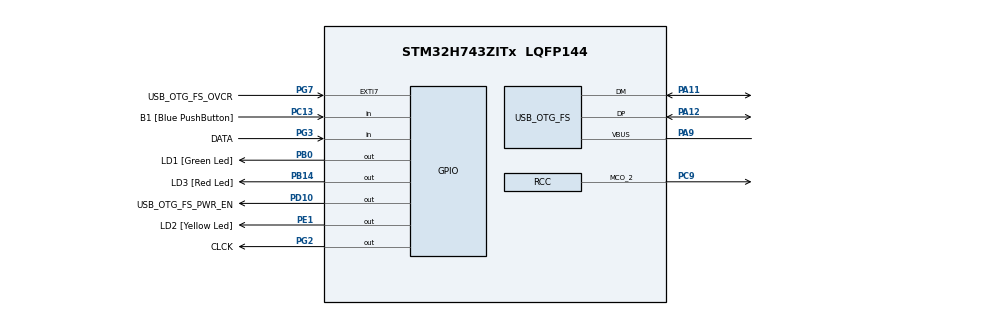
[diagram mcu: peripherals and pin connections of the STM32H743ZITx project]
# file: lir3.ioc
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Mcu.Family=STM32H7
Mcu.Name=STM32H743ZITx
Mcu.Package=LQFP144
NVIC.OTG_FS_IRQn=true\:0\:0\:false\:false\:true\:false\:true
NVIC.PriorityGroup=NVIC_PRIORITYGROUP_4
NVIC.TIM1_UP_IRQn=true\:0\:0\:false\:false\:true\:true\:true
NVIC.TIM2_IRQn=true\:0\:0\:false\:false\:true\:true\:true
PA11.Mode=Device_Only
PA11.Signal=USB_OTG_FS_DM
PA12.Mode=Device_Only
PA12.Signal=USB_OTG_FS_DP
PA13\ (JTMS/SWDIO).Mode=Serial_Wire
PA13\ (JTMS/SWDIO).Signal=DEBUG_JTMS-SWDIO
PA14\ (JTCK/SWCLK).Mode=Serial_Wire
PA14\ (JTCK/SWCLK).Signal=DEBUG_JTCK-SWCLK
PA8.Signal=USB_OTG_FS_SOF
PA9.Mode=Activate_VBUS
PA9.Signal=USB_OTG_FS_VBUS
PB0.GPIO_Label=LD1 [Green Led]
PB0.Signal=GPIO_Output
PB14.GPIO_Label=LD3 [Red Led]
PB14.Signal=GPIO_Output
PC1.Signal=SAI1_SD_A
PC13.GPIO_Label=B1 [Blue PushButton]
PC13.Signal=GPIO_Input
PC14-OSC32_IN\ (OSC32_IN).Signal=RCC_OSC32_IN
PC15-OSC32_OUT\ (OSC32_OUT).Signal=RCC_OSC32_OUT
PC9.Mode=Clock-out-2
PC9.Signal=RCC_MCO_2
PD10.GPIO_Label=USB_OTG_FS_PWR_EN
PD10.Signal=GPIO_Output
PD8.GPIO_Label=STLINK_RX
PD8.Signal=USART3_TX
PD9.GPIO_Label=STLINK_TX
PD9.Signal=USART3_RX
PE1.GPIO_Label=LD2 [Yellow Led]
PE1.Signal=GPIO_Output
PG2.GPIO_Label=CLCK
PG2.GPIO_PuPd=GPIO_PULLUP
PG2.GPIO_Speed=GPIO_SPEED_FREQ_LOW
PG2.PinState=GPIO_PIN_SET
PG2.Signal=GPIO_Output
PG3.GPIO_Label=DATA
PG3.GPIO_PuPd=GPIO_PULLUP
PG3.Signal=GPIO_Input
PG7.GPIO_Label=USB_OTG_FS_OVCR
PG7.Signal=GPXTI7
PH0-OSC_IN\ (PH0).Mode=HSE-External-Oscillator
PH0-OSC_IN\ (PH0).Signal=RCC_OSC_IN
PH1-OSC_OUT\ (PH1).Mode=HSE-External-Oscillator
PH1-OSC_OUT\ (PH1).Signal=RCC_OSC_OUT
ProjectManager.HeapSize=0x200
ProjectManager.StackSize=0x400
ProjectManager.TargetToolchain=STM32CubeIDE
RCC.ADCFreq_Value=129000000
RCC.APB1Freq_Value=120000000
RCC.APB2Freq_Value=120000000
RCC.APB3Freq_Value=120000000
RCC.APB4Freq_Value=120000000
RCC.CortexFreq_Value=480000000
RCC.D1PPRE=RCC_APB3_DIV2
RCC.D2PPRE1=RCC_APB1_DIV2
RCC.D2PPRE2=RCC_APB2_DIV2
RCC.D3PPRE=RCC_APB4_DIV2
RCC.DIVM1=12
RCC.DIVN1=180
RCC.HCLKFreq_Value=240000000
RCC.HPRE=RCC_HCLK_DIV2
RCC.HSE_VALUE=25000000
RCC.SYSCLKFreq_VALUE=480000000
RCC.SYSCLKSource=RCC_SYSCLKSOURCE_PLLCLK
RCC.USBCLockSelection=RCC_USBCLKSOURCE_HSI48
RCC.USBFreq_Value=48000000
TIM1.Period=24
TIM1.Prescaler=23
TIM2.Channel-Output\ Compare1\ No\ Output=TIM_CHANNEL_1
TIM2.Period=149
TIM2.Prescaler=239
USB_DEVICE.CLASS_NAME_FS=CDC
USB_DEVICE.VirtualMode-CDC_FS=Cdc
USB_DEVICE.VirtualModeFS=Cdc_FS
USB_OTG_FS.VirtualMode=Device_Only
VP_TIM1_VS_ClockSourceINT.Mode=Internal
VP_TIM2_VS_ClockSourceINT.Mode=Internal
VP_TIM2_VS_no_output1.Mode=Output Compare1 No Output
VP_USB_DEVICE_VS_USB_DEVICE_CDC_FS.Mode=CDC_FS
board=NUCLEO-H743ZI2

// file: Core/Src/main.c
/* USER CODE BEGIN Header */
/**
  ******************************************************************************
  * @file           : main.c
  * @brief          : Main program body
  ******************************************************************************
  * @attention
  *
  * <h2><center>&copy; Copyright (c) 2021 STMicroelectronics.
  * All rights reserved.</center></h2>
  *
  * This software component is licensed by ST under BSD 3-Clause license,
  * the "License"; You may not use this file except in compliance with the
  * License. You may obtain a copy of the License at:
  *                        opensource.org/licenses/BSD-3-Clause
  *
  ******************************************************************************
  */
/* USER CODE END Header */
#include "main.h"
#include "usb_device.h"

TIM_HandleTypeDef htim1;
TIM_HandleTypeDef htim2;

void SystemClock_Config(void);
static void MX_GPIO_Init(void);
static void MX_TIM1_Init(void);
static void MX_TIM2_Init(void);

int main(void)
{

  /* MCU Configuration--------------------------------------------------------*/

  /* Reset of all peripherals, Initializes the Flash interface and the Systick. */
  HAL_Init();

  /* Configure the system clock */
  SystemClock_Config();

  /* Initialize all configured peripherals */
  MX_GPIO_Init();
  MX_TIM1_Init();
  MX_TIM2_Init();
  MX_USB_DEVICE_Init();
  /* USER CODE BEGIN 2 */

  DWTinit();
  lirInit();

//  TIM1->CCER|=TIM_CCER_CC1E; //map to pins (pin PE9)
//  TIM1->BDTR|=TIM_BDTR_MOE; //main output enable
  TIM2->CR1|= TIM_CR1_CEN;
  TIM2->DIER|= TIM2_IRQn;
  /* USER CODE END 2 */

  /* Infinite loop */
  while (1)
  {

  }
}

void SystemClock_Config(void)
{
  RCC_OscInitTypeDef RCC_OscInitStruct = {0};
  RCC_ClkInitTypeDef RCC_ClkInitStruct = {0};

  /** Supply configuration update enable
  */
  HAL_PWREx_ConfigSupply(PWR_LDO_SUPPLY);
  /** Configure the main internal regulator output voltage
  */
  __HAL_PWR_VOLTAGESCALING_CONFIG(PWR_REGULATOR_VOLTAGE_SCALE0);

  while(!__HAL_PWR_GET_FLAG(PWR_FLAG_VOSRDY)) {}
  /** Initializes the RCC Oscillators according to the specified parameters
  * in the RCC_OscInitTypeDef structure.
  */
  RCC_OscInitStruct.OscillatorType = RCC_OSCILLATORTYPE_HSI48|RCC_OSCILLATORTYPE_HSI;
  RCC_OscInitStruct.HSIState = RCC_HSI_DIV1;
  RCC_OscInitStruct.HSICalibrationValue = RCC_HSICALIBRATION_DEFAULT;
  RCC_OscInitStruct.HSI48State = RCC_HSI48_ON;
  RCC_OscInitStruct.PLL.PLLState = RCC_PLL_ON;
  RCC_OscInitStruct.PLL.PLLSource = RCC_PLLSOURCE_HSI;
  RCC_OscInitStruct.PLL.PLLM = 12;
  RCC_OscInitStruct.PLL.PLLN = 180;
  RCC_OscInitStruct.PLL.PLLP = 2;
  RCC_OscInitStruct.PLL.PLLQ = 2;
  RCC_OscInitStruct.PLL.PLLR = 2;
  RCC_OscInitStruct.PLL.PLLRGE = RCC_PLL1VCIRANGE_2;
  RCC_OscInitStruct.PLL.PLLVCOSEL = RCC_PLL1VCOWIDE;
  RCC_OscInitStruct.PLL.PLLFRACN = 0;
  if (HAL_RCC_OscConfig(&RCC_OscInitStruct) != HAL_OK)
  {
    Error_Handler();
  }
  /** Initializes the CPU, AHB and APB buses clocks
  */
  RCC_ClkInitStruct.ClockType = RCC_CLOCKTYPE_HCLK|RCC_CLOCKTYPE_SYSCLK
                              |RCC_CLOCKTYPE_PCLK1|RCC_CLOCKTYPE_PCLK2
                              |RCC_CLOCKTYPE_D3PCLK1|RCC_CLOCKTYPE_D1PCLK1;
  RCC_ClkInitStruct.SYSCLKSource = RCC_SYSCLKSOURCE_PLLCLK;
  RCC_ClkInitStruct.SYSCLKDivider = RCC_SYSCLK_DIV1;
  RCC_ClkInitStruct.AHBCLKDivider = RCC_HCLK_DIV2;
  RCC_ClkInitStruct.APB3CLKDivider = RCC_APB3_DIV2;
  RCC_ClkInitStruct.APB1CLKDivider = RCC_APB1_DIV2;
  RCC_ClkInitStruct.APB2CLKDivider = RCC_APB2_DIV2;
  RCC_ClkInitStruct.APB4CLKDivider = RCC_APB4_DIV2;

  if (HAL_RCC_ClockConfig(&RCC_ClkInitStruct, FLASH_LATENCY_4) != HAL_OK)
  {
    Error_Handler();
  }
  HAL_RCC_MCOConfig(RCC_MCO2, RCC_MCO2SOURCE_SYSCLK, RCC_MCODIV_1);
}

static void MX_TIM1_Init(void)
{

  TIM_ClockConfigTypeDef sClockSourceConfig = {0};
  TIM_MasterConfigTypeDef sMasterConfig = {0};

  htim1.Instance = TIM1;
  htim1.Init.Prescaler = 23;
  htim1.Init.CounterMode = TIM_COUNTERMODE_UP;
  htim1.Init.Period = 24;
  htim1.Init.ClockDivision = TIM_CLOCKDIVISION_DIV1;
  htim1.Init.RepetitionCounter = 0;
  htim1.Init.AutoReloadPreload = TIM_AUTORELOAD_PRELOAD_DISABLE;
  if (HAL_TIM_Base_Init(&htim1) != HAL_OK)
  {
    Error_Handler();
  }
  sClockSourceConfig.ClockSource = TIM_CLOCKSOURCE_INTERNAL;
  if (HAL_TIM_ConfigClockSource(&htim1, &sClockSourceConfig) != HAL_OK)
  {
    Error_Handler();
  }
  sMasterConfig.MasterOutputTrigger = TIM_TRGO_RESET;
  sMasterConfig.MasterOutputTrigger2 = TIM_TRGO2_RESET;
  sMasterConfig.MasterSlaveMode = TIM_MASTERSLAVEMODE_DISABLE;
  if (HAL_TIMEx_MasterConfigSynchronization(&htim1, &sMasterConfig) != HAL_OK)
  {
    Error_Handler();
  }

}

static void MX_TIM2_Init(void)
{

  TIM_ClockConfigTypeDef sClockSourceConfig = {0};
  TIM_MasterConfigTypeDef sMasterConfig = {0};
  TIM_OC_InitTypeDef sConfigOC = {0};

  htim2.Instance = TIM2;
  htim2.Init.Prescaler = 239;
  htim2.Init.CounterMode = TIM_COUNTERMODE_UP;
  htim2.Init.Period = 149;
  htim2.Init.ClockDivision = TIM_CLOCKDIVISION_DIV1;
  htim2.Init.AutoReloadPreload = TIM_AUTORELOAD_PRELOAD_DISABLE;
  if (HAL_TIM_Base_Init(&htim2) != HAL_OK)
  {
    Error_Handler();
  }
  sClockSourceConfig.ClockSource = TIM_CLOCKSOURCE_INTERNAL;
  if (HAL_TIM_ConfigClockSource(&htim2, &sClockSourceConfig) != HAL_OK)
  {
    Error_Handler();
  }
  if (HAL_TIM_OC_Init(&htim2) != HAL_OK)
  {
    Error_Handler();
  }
  sMasterConfig.MasterOutputTrigger = TIM_TRGO_RESET;
  sMasterConfig.MasterSlaveMode = TIM_MASTERSLAVEMODE_DISABLE;
  if (HAL_TIMEx_MasterConfigSynchronization(&htim2, &sMasterConfig) != HAL_OK)
  {
    Error_Handler();
  }
  sConfigOC.OCMode = TIM_OCMODE_TIMING;
  sConfigOC.Pulse = 0;
  sConfigOC.OCPolarity = TIM_OCPOLARITY_HIGH;
  sConfigOC.OCFastMode = TIM_OCFAST_DISABLE;
  if (HAL_TIM_OC_ConfigChannel(&htim2, &sConfigOC, TIM_CHANNEL_1) != HAL_OK)
  {
    Error_Handler();
  }

}

static void MX_GPIO_Init(void)
{
  GPIO_InitTypeDef GPIO_InitStruct = {0};

  /* GPIO Ports Clock Enable */
  __HAL_RCC_GPIOC_CLK_ENABLE();
  __HAL_RCC_GPIOH_CLK_ENABLE();
  __HAL_RCC_GPIOB_CLK_ENABLE();
  __HAL_RCC_GPIOD_CLK_ENABLE();
  __HAL_RCC_GPIOG_CLK_ENABLE();
  __HAL_RCC_GPIOA_CLK_ENABLE();
  __HAL_RCC_GPIOE_CLK_ENABLE();

  /*Configure GPIO pin Output Level */
  HAL_GPIO_WritePin(GPIOB, LD1_Pin|LD3_Pin, GPIO_PIN_RESET);

  /*Configure GPIO pin Output Level */
  HAL_GPIO_WritePin(USB_OTG_FS_PWR_EN_GPIO_Port, USB_OTG_FS_PWR_EN_Pin, GPIO_PIN_RESET);

  /*Configure GPIO pin Output Level */
  HAL_GPIO_WritePin(CLCK_GPIO_Port, CLCK_Pin, GPIO_PIN_SET);

  /*Configure GPIO pin Output Level */
  HAL_GPIO_WritePin(LD2_GPIO_Port, LD2_Pin, GPIO_PIN_RESET);

  /*Configure GPIO pin : B1_Pin */
  GPIO_InitStruct.Pin = B1_Pin;
  GPIO_InitStruct.Mode = GPIO_MODE_INPUT;
  GPIO_InitStruct.Pull = GPIO_NOPULL;
  HAL_GPIO_Init(B1_GPIO_Port, &GPIO_InitStruct);

  /*Configure GPIO pin : PC1 */
  GPIO_InitStruct.Pin = GPIO_PIN_1;
  GPIO_InitStruct.Mode = GPIO_MODE_AF_PP;
  GPIO_InitStruct.Pull = GPIO_NOPULL;
  GPIO_InitStruct.Speed = GPIO_SPEED_FREQ_LOW;
  GPIO_InitStruct.Alternate = GPIO_AF6_SAI1;
  HAL_GPIO_Init(GPIOC, &GPIO_InitStruct);

  /*Configure GPIO pins : LD1_Pin LD3_Pin */
  GPIO_InitStruct.Pin = LD1_Pin|LD3_Pin;
  GPIO_InitStruct.Mode = GPIO_MODE_OUTPUT_PP;
  GPIO_InitStruct.Pull = GPIO_NOPULL;
  GPIO_InitStruct.Speed = GPIO_SPEED_FREQ_LOW;
  HAL_GPIO_Init(GPIOB, &GPIO_InitStruct);

  /*Configure GPIO pins : STLINK_RX_Pin STLINK_TX_Pin */
  GPIO_InitStruct.Pin = STLINK_RX_Pin|STLINK_TX_Pin;
  GPIO_InitStruct.Mode = GPIO_MODE_AF_PP;
  GPIO_InitStruct.Pull = GPIO_NOPULL;
  GPIO_InitStruct.Speed = GPIO_SPEED_FREQ_LOW;
  GPIO_InitStruct.Alternate = GPIO_AF7_USART3;
  HAL_GPIO_Init(GPIOD, &GPIO_InitStruct);

  /*Configure GPIO pin : USB_OTG_FS_PWR_EN_Pin */
  GPIO_InitStruct.Pin = USB_OTG_FS_PWR_EN_Pin;
  GPIO_InitStruct.Mode = GPIO_MODE_OUTPUT_PP;
  GPIO_InitStruct.Pull = GPIO_NOPULL;
  GPIO_InitStruct.Speed = GPIO_SPEED_FREQ_LOW;
  HAL_GPIO_Init(USB_OTG_FS_PWR_EN_GPIO_Port, &GPIO_InitStruct);

  /*Configure GPIO pin : CLCK_Pin */
  GPIO_InitStruct.Pin = CLCK_Pin;
  GPIO_InitStruct.Mode = GPIO_MODE_OUTPUT_PP;
  GPIO_InitStruct.Pull = GPIO_PULLUP;
  GPIO_InitStruct.Speed = GPIO_SPEED_FREQ_LOW;
  HAL_GPIO_Init(CLCK_GPIO_Port, &GPIO_InitStruct);

  /*Configure GPIO pin : DATA_Pin */
  GPIO_InitStruct.Pin = DATA_Pin;
  GPIO_InitStruct.Mode = GPIO_MODE_INPUT;
  GPIO_InitStruct.Pull = GPIO_PULLUP;
  HAL_GPIO_Init(DATA_GPIO_Port, &GPIO_InitStruct);

  /*Configure GPIO pin : USB_OTG_FS_OVCR_Pin */
  GPIO_InitStruct.Pin = USB_OTG_FS_OVCR_Pin;
  GPIO_InitStruct.Mode = GPIO_MODE_IT_RISING;
  GPIO_InitStruct.Pull = GPIO_NOPULL;
  HAL_GPIO_Init(USB_OTG_FS_OVCR_GPIO_Port, &GPIO_InitStruct);

  /*Configure GPIO pin : PC9 */
  GPIO_InitStruct.Pin = GPIO_PIN_9;
  GPIO_InitStruct.Mode = GPIO_MODE_AF_PP;
  GPIO_InitStruct.Pull = GPIO_NOPULL;
  GPIO_InitStruct.Speed = GPIO_SPEED_FREQ_LOW;
  GPIO_InitStruct.Alternate = GPIO_AF0_MCO;
  HAL_GPIO_Init(GPIOC, &GPIO_InitStruct);

  /*Configure GPIO pin : LD2_Pin */
  GPIO_InitStruct.Pin = LD2_Pin;
  GPIO_InitStruct.Mode = GPIO_MODE_OUTPUT_PP;
  GPIO_InitStruct.Pull = GPIO_NOPULL;
  GPIO_InitStruct.Speed = GPIO_SPEED_FREQ_LOW;
  HAL_GPIO_Init(LD2_GPIO_Port, &GPIO_InitStruct);

}

void Error_Handler(void)
{
  __disable_irq();
  while (1)
  {
  }
}

/************************ (C) COPYRIGHT STMicroelectronics *****END OF FILE****/
